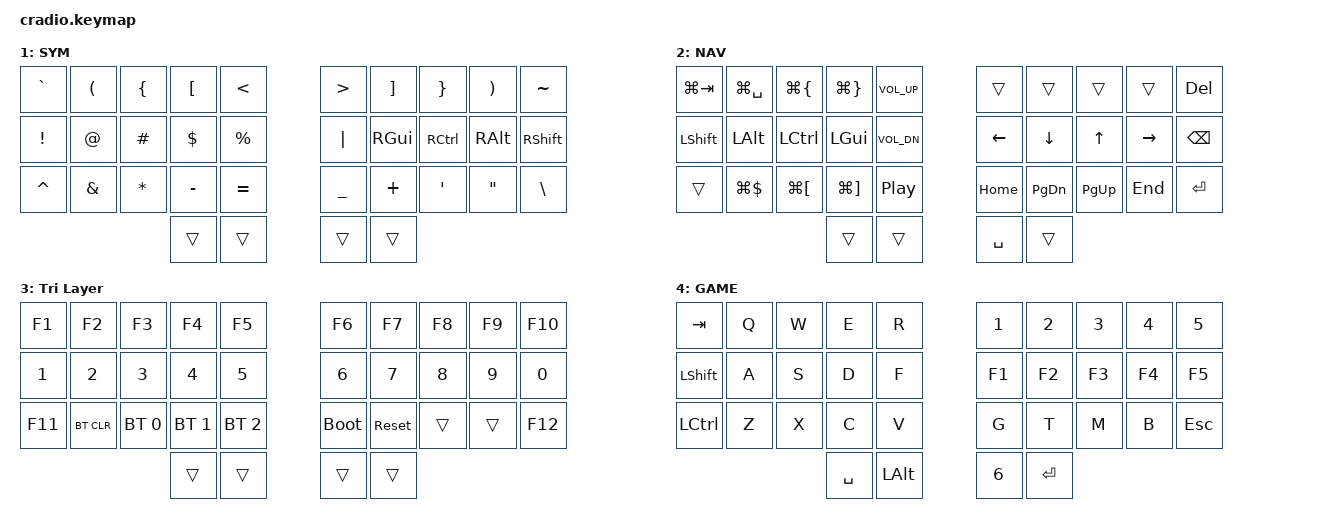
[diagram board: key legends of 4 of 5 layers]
// Copyright (c) 2022 The ZMK Contributors
// SPDX-License-Identifier: MIT

#include <behaviors.dtsi>
#include <dt-bindings/zmk/keys.h>
#include <dt-bindings/zmk/bt.h>
#include <dt-bindings/zmk/pointing.h>

// Home row mods macro
#define HRML(k1,k2,k3,k4) &ht LSHFT k1  &ht LALT k2  &ht LCTRL k3  &ht LGUI k4
#define HRMR(k1,k2,k3,k4) &ht RGUI k1  &ht RCTRL k2  &ht RALT k3  &ht RSHFT k4

/ {
    behaviors {
        ht: hold_tap {
            compatible = "zmk,behavior-hold-tap";
            #binding-cells = <2>;
            flavor = "tap-preferred";
            tapping-term-ms = <200>;
            quick-tap-ms = <150>;
            require-prior-idle-ms = <100>;
            bindings = <&kp>, <&kp>;
        };
        tog_game_hold: tog_game_hold {
            compatible = "zmk,behavior-hold-tap";
            #binding-cells = <2>;
            flavor = "hold-preferred";
            tapping-term-ms = <2000>;
            bindings = <&tog>, <&none>;
        };
    };

    conditional_layers {
        compatible = "zmk,conditional-layers";
        tri_layer {
            if-layers = <1 2>;
            then-layer = <3>;
        };
    };

    combos {
        compatible = "zmk,combos";
        timeout-ms = <50>;

        combo_tab {
            key-positions = <1 2>; // W + E
            bindings = <&kp TAB>;
        };

        combo_esc {
            key-positions = <11 12>;
            bindings = <&kp ESC>; // S + D
        };

        combo_del {
            key-positions = <7 8>;
            bindings = <&kp DEL>; // I + O
        };

        combo_bck {
            key-positions = <17 18>;
            bindings = <&kp BSPC>; // K + L
        };

        combo_ent {
            key-positions = <27 28>;
            bindings = <&kp ENTER>; // , + .
        };

         combo_game_toggle {
            timeout-ms = <50>;
            key-positions = <8 9>;  // O + P positions
            bindings = <&tog_game_hold 4 0>;
            layers = <0 4>;  // Active on base and game layers
        };
    };

    keymap {
        compatible = "zmk,keymap";

        // ─────────────────────────── QWERTY ───────────────────────────
        default_layer {
            display-name = "COLEMAK";
            bindings = <
        // ╭─────────┬─────────┬─────────┬─────────┬─────────╮   ╭─────────┬─────────┬─────────┬─────────┬─────────╮
        // │   Q     │   W     │   E     │   R     │   T     │   │   Y     │   U     │   I     │   O     │   P     │
            &kp Q      &kp W     &kp F     &kp P     &kp B        &kp J     &kp L     &kp U     &kp Y     &kp SEMI
        // ├─────────┼─────────┼─────────┼─────────┼─────────┤   ├─────────┼─────────┼─────────┼─────────┼─────────┤
        // │   A     │   S     │   D     │   F     │   G     │   │   H     │   J     │   K     │   L     │ ; :     │
            HRML(A,      R,        S,        T)      &kp G          &kp M   HRMR(N,      E,        I,        O)
        // ├─────────┼─────────┼─────────┼─────────┼─────────┤   ├─────────┼─────────┼─────────┼─────────┼─────────┤
        // │   Z     │   X     │   C     │   V     │   B     │   │   N     │   M     │ , <     │ . >     │ / ?     │
            &kp Z      &kp X     &kp C     &kp D     &kp V        &kp K     &kp H     &kp COMMA &kp DOT   &kp SLASH
        // ╰─────────┴─────────┴─────────┼─────────┼─────────┤   ├─────────┼─────────┼─────────┴─────────┴─────────╯
                                          &lt 2 TAB &ht LSHFT BSPC   &kp SPACE &lt 1 ENTER
        //                               ╰─────────┴─────────╯   ╰─────────┴─────────╯
            >;
        };

        // ─────────────────────────── SYMBOLS ───────────────────────────
        right_layer {
            display-name = "SYM";
            bindings = <
        // ╭─────────┬─────────┬─────────┬─────────┬─────────╮   ╭─────────┬─────────┬─────────┬─────────┬─────────╮
        // │   `     │   (     │   {     │   [     │   <     │   │   >     │   ]     │   }     │   )     │   ~     │
            &kp GRAVE &kp LPAR &kp LBRC  &kp LBKT  &kp LT        &kp GT    &kp RBKT  &kp RBRC  &kp RPAR  &kp TILDE
        // ├─────────┼─────────┼─────────┼─────────┼─────────┤   ├─────────┼─────────┼─────────┼─────────┼─────────┤
        // │   !     │   @     │   #     │   $     │   %     │   │   |     │  GUI    │  CTRL   │  ALT    │  SHIFT  │
            &kp EXCL  &kp AT   &kp HASH  &kp DLLR  &kp PRCNT      &kp PIPE   &kp RGUI  &kp RCTRL &kp RALT  &kp RSHFT
        // ├─────────┼─────────┼─────────┼─────────┼─────────┤   ├─────────┼─────────┼─────────┼─────────┼─────────┤
        // │   ^     │   &     │   *     │   -     │   =     │   │   _     │   +     │   '     │   "     │   \     │
            &kp CARET &kp AMPS &kp STAR  &kp MINUS &kp EQUAL      &kp UNDER &kp PLUS  &kp SQT   &kp DQT   &kp BACKSLASH
        // ╰─────────┴─────────┴─────────┼─────────┼─────────┤   ├─────────┼─────────┼─────────┴─────────┴─────────╯
                                          &trans    &trans         &trans   &trans
        //                               ╰─────────┴─────────╯   ╰─────────┴─────────╯
            >;
        };

        // ─────────────────────────── NAVIGATION ───────────────────────────
        left_layer {
            display-name = "NAV";
            bindings = <
        // ╭─────────┬──────────┬──────────┬──────────┬──────────╮               ╭──────────┬──────────┬──────────┬──────────┬──────────╮
        // │ GUI+TAB │ GUI+SPC  │ GUI+{    │ GUI+}    │ Vol+     │               │ ←        │ ↓        │ ↑        │ →        │ Delete   │
            &kp LG(TAB)  &kp LG(SPACE) &kp LG(LBRC) &kp LG(RBRC) &kp C_VOL_UP      &trans &trans &trans &trans  &kp DEL
        // ├─────────┼──────────┼──────────┼──────────┼──────────┤               ├──────────┼──────────┼──────────┼──────────┼──────────┤
        // │ Shift   │ Alt      │ Ctrl     │ GUI      │ Vol-     │               │ Home     │ PgDn     │ PgUp     │ End      │ Enter    │
            &kp LSHFT   &kp LALT     &kp LCTRL    &kp LGUI &kp C_VOL_DN         &kp LEFT   &kp DOWN   &kp UP     &kp RIGHT  &kp BSPC
        // ├─────────┼──────────┼──────────┼──────────┼──────────┤               ├──────────┼──────────┼──────────┼──────────┼──────────┤
        // │ (unused)│ GUI+$    │ GUI+[    │ GUI+]    │ Play/Pause│              │ (unused) │ (unused) │ (unused) │ (unused) │ (unused) │
            &trans    &kp LG(DOLLAR) &kp LG(LBKT) &kp LG(RBKT) &kp C_PLAY_PAUSE &kp HOME   &kp PG_DN   &kp PG_UP   &kp END    &kp ENTER
        // ╰─────────┴──────────┴──────────┼──────────┼──────────┤               ├──────────┼──────────┼──────────┴──────────┴──────────╯
                                           &trans     &trans                     &kp SPACE   &trans
        //                                ╰──────────┴──────────╯                ╰──────────┴──────────╯
            >;
        };

        // ─────────────────────────── TRI-LAYER (FN / SYSTEM) ───────────────────────────
        tri_layer {
            display-name = "Tri Layer";
            bindings = <
        // ╭─────────┬──────────┬──────────┬──────────┬──────────╮   ╭──────────┬──────────┬──────────┬──────────┬──────────╮
        // │ F1      │ F2       │ F3       │ F4       │ F5       │   │ F6       │ F7       │ F8       │ F9       │ F10      │
            &kp F1     &kp F2     &kp F3     &kp F4     &kp F5       &kp F6     &kp F7     &kp F8     &kp F9     &kp F10
        // ├─────────┼──────────┼──────────┼──────────┼──────────┤   ├──────────┼──────────┼──────────┼──────────┼──────────┤
        // │ 1       │ 2        │ 3        │ 4        │ 5        │   │ 6        │ 7        │ 8        │ 9        │ 0        │
            &kp N1     &kp N2     &kp N3     &kp N4     &kp N5       &kp N6     &kp N7     &kp N8     &kp N9     &kp N0
        // ├─────────┼──────────┼──────────┼──────────┼──────────┤   ├──────────┼──────────┼──────────┼──────────┼──────────┤
        // │ F11     │ BT Clear │ BT Sel 0 │ BT Sel 1 │ BT Sel 2 │   │ Boot     │ Reset    │ (unused) │ (unused) │ F12      │
            &kp F11    &bt BT_CLR &bt BT_SEL 0 &bt BT_SEL 1 &bt BT_SEL 2 &bootloader &sys_reset &trans &trans &kp F12
        // ╰─────────┴──────────┴──────────┼──────────┼──────────┤   ├──────────┼──────────┼──────────┴──────────┴──────────╯
                                           &trans     &trans        &trans     &trans
        //                                ╰──────────┴──────────╯   ╰──────────┴──────────╯
            >;
        };

        game {
            display-name = "GAME";
            bindings = <
        //╭──────────┬──────────┬──────────┬──────────┬──────────╮   ╭──────────┬──────────┬──────────┬──────────┬──────────╮
        //│  TAB     │  Q       │  W       │  E       │  R       │   │  1       │  2       │  3       │  4       │  5       │
            &kp TAB    &kp Q      &kp W      &kp E      &kp R          &kp N1     &kp N2     &kp N3     &kp N4     &kp N5
        //├──────────┼──────────┼──────────┼──────────┼──────────┤   ├──────────┼──────────┼──────────┼──────────┼──────────┤
        //│  LSHIFT  │  A       │  S       │  D       │  F       │   │  F1      │  F2      │  F3      │  F4      │  F5      │
            &kp LSHIFT &kp A      &kp S      &kp D      &kp F          &kp F1     &kp F2     &kp F3     &kp F4     &kp F5
        //├──────────┼──────────┼──────────┼──────────┼──────────┤   ├──────────┼──────────┼──────────┼──────────┼──────────┤
        //│  LCTRL   │  Z       │  X       │  C       │  V       │   │  G       │  T       │  M       │  B       │  ESC     │
            &kp LCTRL  &kp Z      &kp X      &kp C      &kp V          &kp G      &kp T      &kp M      &kp B      &kp ESC
        //╰──────────┴──────────┴──────────┼──────────┼──────────┤   ├──────────┼──────────┼──────────┴──────────┴──────────╯
                                            &kp SPACE  &kp LALT       &kp N6     &kp ENTER
        //                                 ╰──────────┴──────────╯   ╰──────────┴──────────╯
            >;
        };
    };
};
